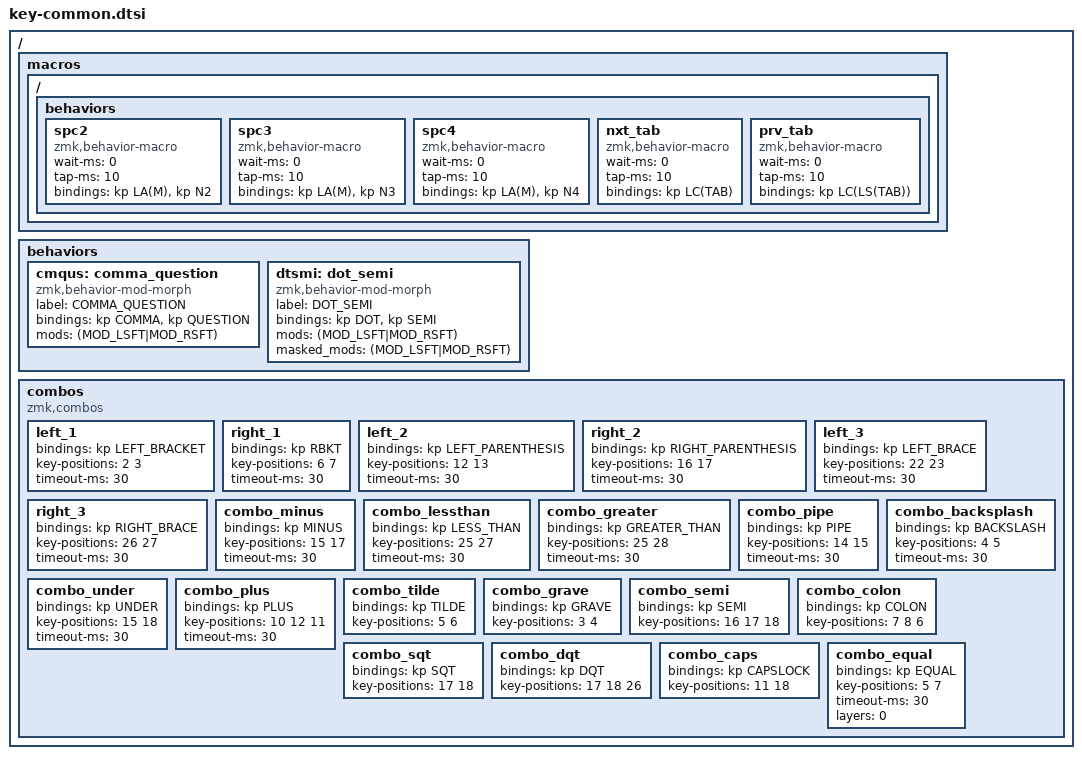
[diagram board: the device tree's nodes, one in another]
#define DEFAULT 0
#define QWERT   1
#define NUM     2
#define SYM     3

/ {
    // macros
    macros {
      ZMK_MACRO(unstick, //ZM_unstick
        compatible = "zmk,behavior-macro";
        wait-ms = <0>;
        tap-ms  = <10>;
        #binding-cells = <0>;
        bindings = <&kp LSHIFT &kp RSHIFT &kp LCTRL &kp RCTRL &kp LALT &kp RALT &kp LGUI &kp RGUI>;
      )

      ZMK_MACRO(spc1, // for spacemacs window nav, Alt+M+1
        wait-ms = <0>;
        tap-ms  = <10>;
        bindings = <&kp LA(M) &kp N1>;
      )
    
      ZMK_MACRO(spc2,
        wait-ms = <0>;
        tap-ms  = <10>;
        bindings = <&kp LA(M) &kp N2>;
      )
    
      ZMK_MACRO(spc3,
        wait-ms = <0>;
        tap-ms  = <10>;
        bindings = <&kp LA(M) &kp N3>;
      )

      ZMK_MACRO(spc4,
        wait-ms = <0>;
        tap-ms  = <10>;
        bindings = <&kp LA(M) &kp N4>;
      )

      ZMK_MACRO(nxt_tab,
        wait-ms = <0>;
        tap-ms  = <10>;
        bindings = <&kp LC(TAB)>;
      )

      ZMK_MACRO(prv_tab,
        wait-ms = <0>;
        tap-ms  = <10>;
        bindings = <&kp LC(LS(TAB))>;
      )
    };
   
    // custom shift using mod-morph 
    behaviors {
      cmqus: comma_question {
        compatible = "zmk,behavior-mod-morph";
        label = "COMMA_QUESTION";
        #binding-cells = <0>;
        bindings = <&kp COMMA>, <&kp QUESTION>;
        mods = <(MOD_LSFT|MOD_RSFT)>;
      };

      dtsmi: dot_semi {
        compatible = "zmk,behavior-mod-morph";
        label = "DOT_SEMI";
        #binding-cells = <0>;
        bindings = <&kp DOT>, <&kp SEMI>;
        mods = <(MOD_LSFT|MOD_RSFT)>;
        masked_mods = <(MOD_LSFT|MOD_RSFT)>; // don't send shift
      };
    };

    // combos
    combos {
        compatible = "zmk,combos";
        
        // both right thumb keys
        // internal-left & external-right thumb keys
        // both left thumb keys

        left_1 {
            bindings = <&kp LEFT_BRACKET>;
            key-positions = <2 3>;
            timeout-ms = <30>;
        };

        right_1 {
            bindings = <&kp RBKT>;
            key-positions = <6 7>;
            timeout-ms = <30>;
        };

        left_2 {
            bindings = <&kp LEFT_PARENTHESIS>;
            key-positions = <12 13>;
            timeout-ms = <30>;
        };

        right_2 {
            bindings = <&kp RIGHT_PARENTHESIS>;
            key-positions = <16 17>;
            timeout-ms = <30>;
        };

        left_3 {
            bindings = <&kp LEFT_BRACE>;
            key-positions = <22 23>;
            timeout-ms = <30>;
        };

        right_3 {
            bindings = <&kp RIGHT_BRACE>;
            key-positions = <26 27>;
            timeout-ms = <30>;
        };

        combo_minus {
            bindings = <&kp MINUS>;
            key-positions = <15 17>;
            timeout-ms = <30>;
        };

        combo_lessthan {
            bindings = <&kp LESS_THAN>;
            key-positions = <25 27>;
            timeout-ms = <30>;
        };

        combo_greater {
            bindings = <&kp GREATER_THAN>;
            key-positions = <25 28>;
            timeout-ms = <30>;
        };

        combo_pipe {
            bindings = <&kp PIPE>;
            key-positions = <14 15>;
            timeout-ms = <30>;
        };

        combo_backsplash {
            bindings = <&kp BACKSLASH>;
            key-positions = <4 5>;
            timeout-ms = <30>;
        };

        combo_under {
            bindings = <&kp UNDER>;
            key-positions = <15 18>;
            timeout-ms = <30>;
        };

        combo_plus {
            bindings = <&kp PLUS>;
            key-positions = <10 12 11>;
            timeout-ms = <30>;
        };

        combo_tilde {
            bindings = <&kp TILDE>;
            key-positions = <5 6>;
        };

        combo_grave {
            bindings = <&kp GRAVE>;
            key-positions = <3 4>;
        };

        combo_semi {
            bindings = <&kp SEMI>;
            key-positions = <16 17 18>;
        };

        combo_colon {
            bindings = <&kp COLON>;
            key-positions = <7 8 6>;
        };

        combo_sqt {
            bindings = <&kp SQT>;
            key-positions = <17 18>;
        };

        combo_dqt {
            bindings = <&kp DQT>;
            key-positions = <17 18 26>;
        };

        combo_caps {
            bindings = <&kp CAPSLOCK>;
            key-positions = <11 18>;
        };

        combo_equal {
            bindings = <&kp EQUAL>;
            key-positions = <5 7>;
            timeout-ms = <30>;
            layers = <0>;
        };
    };
};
